# ADuCM322i register map
Vendor: Analog Devices Inc.; Series: ARMCM3; File version: 1.0
CPU: CM3 r2p1, little endian, no MPU, no FPU, 3 interrupt priority bits
Registers are 16-bit, read-write, no defined reset value unless marked. A register's access mark holds for its fields unless they carry their own. Offsets are from the block's base; [hi:lo] are bit positions; {n}, {i} and the like mark numbered series.

## GPIO4 — General Purpose Input Output 4
Base 0x40020100
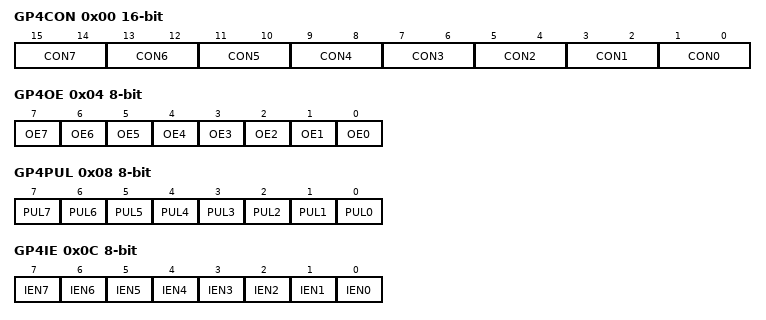
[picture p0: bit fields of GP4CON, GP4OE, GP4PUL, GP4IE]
0x00 GP4CON — GPIO Port 4 Configuration
  [15:14] CON7 range 0x00000000..0x00000003 — p4.7 configuration bits
  [13:12] CON6 range 0x00000000..0x00000003 — p4.6 configuration bits
  [11:10] CON5 range 0x00000000..0x00000003 — p4.5 configuration bits
  [9:8] CON4 range 0x00000000..0x00000003 — p4.4 configuration bits
  [7:6] CON3 range 0x00000000..0x00000003 — p4.3 configuration bits
  [5:4] CON2 range 0x00000000..0x00000003 — p4.2 configuration bits
  [3:2] CON1 range 0x00000000..0x00000003 — p4.1 configuration bits
  [1:0] CON0 — p4.0 configuration bits
    0=GPIO
0x04 GP4OE 8-bit — GPIO Port 4 output enable
  [all] fields
    0=DIS; 1=EN
  [n] OE{n} (n=0..7) — Pin Output Drive enable
0x08 GP4PUL 8-bit — GPIO Port 4 pull down enable
  [all] fields
    0=DIS; 1=EN
  [n] PUL{n} (n=0..7) — Pin Pull down enable
0x0C GP4IE 8-bit — GPIO Port 4 Input Path Enable
  [all] fields
    0=DIS; 1=EN
  [n] IEN{n} (n=0..7) — Input path enable
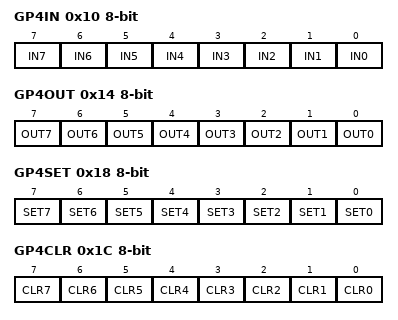
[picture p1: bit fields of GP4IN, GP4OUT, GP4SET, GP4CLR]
0x10 GP4IN 8-bit ro — GPIO Port 4 registered data input
  [all] fields
    0=LOW; 1=HIGH
  [n] IN{n} (n=0..7) — Registered data input
0x14 GP4OUT 8-bit — GPIO Port 4 data output
  [all] fields
    0=LOW; 1=HIGH
  [n] OUT{n} (n=0..7) — Data out
0x18 GP4SET 8-bit wo — GPIO Port 4 data out set
  [all] fields
    1=SET
  [n] SET{n} (n=0..7) — Set the output HIGH for the pin
0x1C GP4CLR 8-bit wo — GPIO Port 4 data out clear
  [all] fields
    1=CLR
  [n] CLR{n} (n=0..7) — Set the output low for the port pin
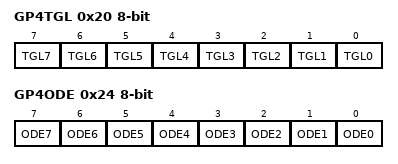
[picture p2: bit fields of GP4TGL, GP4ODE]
0x20 GP4TGL 8-bit wo — GPIO Port 4 pin toggle
  [all] fields
    1=TGL
  [n] TGL{n} (n=0..7) — Toggle the output of the port pin
0x24 GP4ODE 8-bit — GPIO Port 4 open drain enable
  [all] fields
    0=DIS; 1=EN
  [n] ODE{n} (n=0..7) — Open drain enable

## GPIO5 — General Purpose Input Output 5
Base 0x40020240
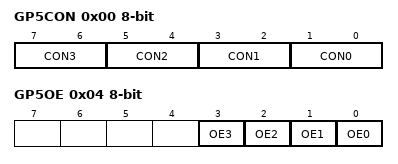
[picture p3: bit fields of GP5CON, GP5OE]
0x00 GP5CON 8-bit — GPIO Port 5 Configuration
  [7:6] CON3 — p5.3 configuration bits
    0=GPIO; 1=VDAC0
  [5:4] CON2 — p5.2 configuration bits
    0=GPIO; 1=VDAC7
  [3:2] CON1 — p5.1 configuration bits
    0=GPIO; 1=VDAC6
  [1:0] CON0 — p5.0 configuration bits
    0=GPIO; 1=VDAC3
0x04 GP5OE 8-bit — GPIO Port 5 output enable
  [all] fields
    0=DIS; 1=EN
  [n] OE{n} (n=0..3) — Pin Output Drive enable
0x08 GP5PUL 4-bit — GPIO Port 5 pull down enable
  [all] fields
    0=DIS; 1=EN
  [n] PUL{n} (n=0..3) — Pin Pull down enable
0x0C GP5IE 4-bit — GPIO Port 5 Input Path Enable
  [all] fields
    0=DIS; 1=EN
  [n] IEN{n} (n=0..3) — Input path enable
0x10 GP5IN 4-bit ro — GPIO Port 5 registered data input
  [all] fields
    0=LOW; 1=HIGH
  [n] IN{n} (n=0..3) — Registered data input
0x14 GP5OUT 4-bit — GPIO Port 5 data output
  [all] fields
    0=LOW; 1=HIGH
  [n] OUT{n} (n=0..3) — Data out
0x18 GP5SET 4-bit wo — GPIO Port 5 data out set
  [all] fields
    1=SET
  [n] SET{n} (n=0..3) — Set the output HIGH for the pin
0x1C GP5CLR 4-bit wo — GPIO Port 5 data out clear
  [all] fields
    1=CLR
  [n] CLR{n} (n=0..3) — Set the output low for the port pin
0x20 GP5TGL 4-bit wo — GPIO Port 5 pin toggle
  [all] fields
    1=TGL
  [n] TGL{n} (n=0..3) — Toggle the output of the port pin
0x24 GP5ODE 4-bit — GPIO Port 5 open drain enable
  [all] fields
    0=DIS; 1=EN
  [n] ODE{n} (n=0..3) — Open drain enable

## PWM — Pulse Width Modulation
Base 0x40024000
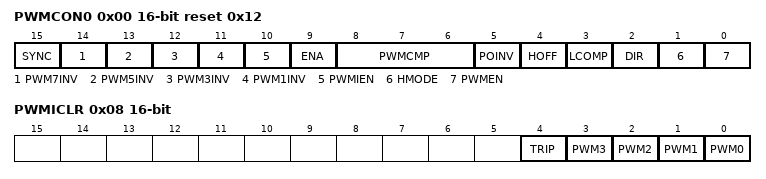
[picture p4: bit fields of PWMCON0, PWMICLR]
0x00 PWMCON0 reset 0x12 (reset mask 0x0) — PWM control register
  [15] SYNC — Set to enable PWM synchronization from the SYNC pin of the PWM
    0=DIS (Ignore transition from the SYNC pin); 1=EN (All PWM counters are reset on the next clock cycle after detection of a falling edge from SYNC pin)
  [14] PWM7INV range 0x00000000..0x00000001 — Set to invert PWM7 output
  [13] PWM5INV range 0x00000000..0x00000001 — Set to invert PWM5 output
  [12] PWM3INV range 0x00000000..0x00000001 — Set to invert PWM3 output
  [11] PWM1INV range 0x00000000..0x00000001 — Set to invert PWM1 output
  [10] PWMIEN range 0x00000000..0x00000001 — Set to enable interrupts for PWM
  [9] ENA — When HOFF=0 and HMODE=1 this serves as enable for Pair 0 and 1
    0=DIS (Disable Pair 0 and 1); 1=EN (Enable Pair 0 and 1)
  [8:6] PWMCMP — PWM Clock prescaler. Sets HCLK divider.
    0=DIV2 (HCLK/2); 1=DIV4 (HCLK/4); 2=DIV8 (HCLK/8); 3=DIV16 (HCLK/16); 4=DIV32 (HCLK/32); 5=DIV64 (HCLK/64); 6=DIV128 (HCLK/128); 7=DIV256 (HCLK/256)
  [5] POINV range 0x00000000..0x00000001 — Set to invert PWM outputs for Pair 0 and 1 when PWM is in H-bridge mode
  [4] HOFF range 0x00000000..0x00000001 — Set to turn off the high-side for Pair 0 and 1 when PWM is in H-bridge mode
  [3] LCOMP — Signal to load a new set of compare register values. In standard mode, this bit is cleared when the new values are loaded in the compare registers for all the channels. In H-bridge mode this bit does not get cleared, but the user must write a value of 1 to this bit in order for the compare registers to be loaded
    0=DIS (Use the values previously store in the compare and length registers); 1=EN (Load the internal compare registers with values stored in the PWMxCOMx and PWMxLEN registers)
  [2] DIR — Direction control when PWM is in H-bridge mode
    0=DIS (PWM2 and PWM3 act as output signals while PWM0 and PWM1 are held low); 1=EN (PWM0 and PWM1 act as output signals while PWM2 and PWM3 are held low)
  [1] HMODE range 0x00000000..0x00000001 — Set to enable H-bridge mode
  [0] PWMEN — Master enable for PWM
    0=DIS (Disable all PWM outputs); 1=EN (Enable all PWM outputs)
0x04 PWMCON1 — ADC conversion start and trip control register
  [6] TRIP_EN range 0x00000000..0x00000001 — Set to enable PWM Trip functionality
0x08 PWMICLR — Hardware trip configuration register
  [4] TRIP range 0x00000000..0x00000001 — Write a 1 to clear latched IRQPWMTrip interrupt. Returns 0 on reads.
  [n] PWM{n} range 0x00000000..0x00000001 (n=0..3) — Write a 1 to clear latched IRQPWM{n} interrupt. Returns 0 on reads.
{0x10+0x10*i} PWM{i}COM0 (i=0..3) — Compare Register 0 for PWM{2i} and PWM{2i+1}
  [15:0] COM0 range 0x00000000..0x0000FFFF — Compare register 0 data
{0x14+0x10*i} PWM{i}COM1 (i=0..3) — Compare Register 1 for PWM{2i} and PWM{2i+1}
  [15:0] COM1 range 0x00000000..0x0000FFFF — Compare register 1 data
{0x18+0x10*i} PWM{i}COM2 (i=0..3) — Compare Register 2 for PWM{2i} and PWM{2i+1}
  [15:0] COM2 range 0x00000000..0x0000FFFF — Compare register 2 data
{0x1C+0x10*i} PWM{i}LEN (i=0..3) — Period value register for PWM{2i} and PWM{2i+1}
  [15:0] LEN range 0x00000000..0x0000FFFF — Period value
